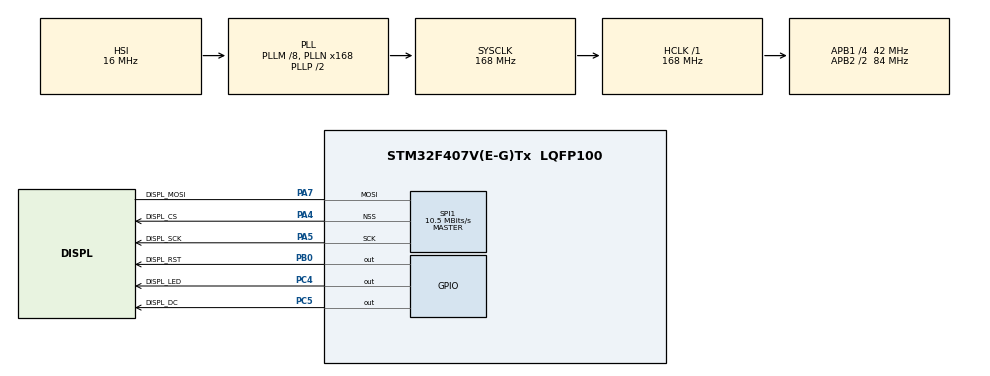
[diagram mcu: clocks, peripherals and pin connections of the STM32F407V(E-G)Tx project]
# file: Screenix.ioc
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Dma.Request0=SPI1_TX
Dma.SPI1_TX.0.Direction=DMA_MEMORY_TO_PERIPH
Dma.SPI1_TX.0.FIFOMode=DMA_FIFOMODE_DISABLE
Dma.SPI1_TX.0.Instance=DMA2_Stream3
Dma.SPI1_TX.0.MemDataAlignment=DMA_MDATAALIGN_BYTE
Dma.SPI1_TX.0.MemInc=DMA_MINC_ENABLE
Dma.SPI1_TX.0.Mode=DMA_NORMAL
Dma.SPI1_TX.0.PeriphDataAlignment=DMA_PDATAALIGN_BYTE
Dma.SPI1_TX.0.PeriphInc=DMA_PINC_DISABLE
Dma.SPI1_TX.0.Priority=DMA_PRIORITY_LOW
Mcu.Family=STM32F4
Mcu.Name=STM32F407V(E-G)Tx
Mcu.Package=LQFP100
NVIC.DMA2_Stream3_IRQn=true\:0\:0\:false\:false\:true\:false\:true\:true
NVIC.PriorityGroup=NVIC_PRIORITYGROUP_4
NVIC.SPI1_IRQn=true\:0\:0\:false\:false\:true\:true\:true\:true
PA13.Mode=Serial_Wire
PA13.Signal=SYS_JTMS-SWDIO
PA14.Mode=Serial_Wire
PA14.Signal=SYS_JTCK-SWCLK
PA4.GPIO_Label=DISPL_CS
PA4.Mode=NSS_Signal_Hard_Output
PA4.Signal=SPI1_NSS
PA5.GPIO_Label=DISPL_SCK
PA5.Mode=Simplex_Bidirectional_Master
PA5.Signal=SPI1_SCK
PA7.GPIO_Label=DISPL_MOSI
PA7.Mode=Simplex_Bidirectional_Master
PA7.Signal=SPI1_MOSI
PB0.GPIO_Label=DISPL_RST
PB0.GPIO_Speed=GPIO_SPEED_FREQ_VERY_HIGH
PB0.Signal=GPIO_Output
PC4.GPIO_Label=DISPL_LED
PC4.GPIO_Speed=GPIO_SPEED_FREQ_VERY_HIGH
PC4.Signal=GPIO_Output
PC5.GPIO_Label=DISPL_DC
PC5.GPIO_Speed=GPIO_SPEED_FREQ_VERY_HIGH
PC5.Signal=GPIO_Output
PH0-OSC_IN.Mode=HSE-External-Oscillator
PH0-OSC_IN.Signal=RCC_OSC_IN
PH1-OSC_OUT.Mode=HSE-External-Oscillator
PH1-OSC_OUT.Signal=RCC_OSC_OUT
ProjectManager.HeapSize=0x200
ProjectManager.StackSize=0x400
ProjectManager.TargetToolchain=Makefile
RCC.48MHZClocksFreq_Value=84000000
RCC.AHBFreq_Value=168000000
RCC.APB1CLKDivider=RCC_HCLK_DIV4
RCC.APB1Freq_Value=42000000
RCC.APB1TimFreq_Value=84000000
RCC.APB2CLKDivider=RCC_HCLK_DIV2
RCC.APB2Freq_Value=84000000
RCC.APB2TimFreq_Value=168000000
RCC.CortexFreq_Value=168000000
RCC.HCLKFreq_Value=168000000
RCC.HSE_VALUE=25000000
RCC.HSI_VALUE=16000000
RCC.LSE_VALUE=32768
RCC.PLLM=8
RCC.PLLN=168
RCC.SYSCLKFreq_VALUE=168000000
RCC.SYSCLKSource=RCC_SYSCLKSOURCE_PLLCLK
RCC.VCOOutputFreq_Value=336000000
SPI1.BaudRatePrescaler=SPI_BAUDRATEPRESCALER_8
SPI1.CalculateBaudRate=10.5 MBits/s
SPI1.Direction=SPI_DIRECTION_1LINE
SPI1.Mode=SPI_MODE_MASTER
SPI1.VirtualNSS=VM_NSSHARD
SPI1.VirtualType=VM_MASTER
board=custom

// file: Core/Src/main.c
/* USER CODE BEGIN Header */
/**
 ******************************************************************************
 * @file           : main.c
 * @brief          : Main program body
 ******************************************************************************
 * @attention
 *
 * Copyright (c) 2024 STMicroelectronics.
 * All rights reserved.
 *
 * This software is licensed under terms that can be found in the LICENSE file
 * in the root directory of this software component.
 * If no LICENSE file comes with this software, it is provided AS-IS.
 *
 ******************************************************************************
 */
/* USER CODE END Header */
#include "main.h"
#include "dma.h"
#include "spi.h"
#include "gpio.h"

/* USER CODE BEGIN PV */
uint8_t sos;

/* USER CODE END PV */

void SystemClock_Config(void);

int main(void)
{

  /* MCU Configuration--------------------------------------------------------*/

  /* Reset of all peripherals, Initializes the Flash interface and the Systick. */
  HAL_Init();

  /* Configure the system clock */
  SystemClock_Config();

  /* Initialize all configured peripherals */
  MX_GPIO_Init();
  MX_DMA_Init();
  MX_SPI1_Init();
  /* USER CODE BEGIN 2 */
  Displ_Init(Displ_Orientat_0); // initialize the display and set the initial display orientation (here is orientaton: 0�) - THIS FUNCTION MUST PRECEED ANY OTHER DISPLAY FUNCTION CALL.
  Displ_CLS(BLACK);             // after initialization (above) and before turning on backlight (below), you can draw the initial display appearance. (here I'm just clearing display with a black background)
                                // Displ_WChar(0, 0, 65, Font24, 1, GREEN, BLACK);
  Displ_WString(20, 52, "12:05", Font24, 1, GREEN, BLACK);
  // Displ_WString(10, 10, "Set time:", Font16, 1, YELLOW, BLACK);
  // Displ_WString(10, 10, "Set alarm:", Font16, 1, YELLOW, BLACK);
  Displ_WString(15, 30, "ALARM!", Font24, 1, RED, BLACK);

  Displ_BackLight('I'); // initialize backlight and turn it on at init level
  Displ_BackLight('F');

  /* USER CODE END 2 */

  /* Infinite loop */
  /* USER CODE BEGIN WHILE */
  while (1)
  {
    // Displ_PerfTest();
    /* USER CODE END WHILE */

  }
}

void SystemClock_Config(void)
{
  RCC_OscInitTypeDef RCC_OscInitStruct = {0};
  RCC_ClkInitTypeDef RCC_ClkInitStruct = {0};

  /** Configure the main internal regulator output voltage
   */
  __HAL_RCC_PWR_CLK_ENABLE();
  __HAL_PWR_VOLTAGESCALING_CONFIG(PWR_REGULATOR_VOLTAGE_SCALE1);

  /** Initializes the RCC Oscillators according to the specified parameters
   * in the RCC_OscInitTypeDef structure.
   */
  RCC_OscInitStruct.OscillatorType = RCC_OSCILLATORTYPE_HSI;
  RCC_OscInitStruct.HSIState = RCC_HSI_ON;
  RCC_OscInitStruct.HSICalibrationValue = RCC_HSICALIBRATION_DEFAULT;
  RCC_OscInitStruct.PLL.PLLState = RCC_PLL_ON;
  RCC_OscInitStruct.PLL.PLLSource = RCC_PLLSOURCE_HSI;
  RCC_OscInitStruct.PLL.PLLM = 8;
  RCC_OscInitStruct.PLL.PLLN = 168;
  RCC_OscInitStruct.PLL.PLLP = RCC_PLLP_DIV2;
  RCC_OscInitStruct.PLL.PLLQ = 4;
  if (HAL_RCC_OscConfig(&RCC_OscInitStruct) != HAL_OK)
  {
    Error_Handler();
  }

  /** Initializes the CPU, AHB and APB buses clocks
   */
  RCC_ClkInitStruct.ClockType = RCC_CLOCKTYPE_HCLK | RCC_CLOCKTYPE_SYSCLK | RCC_CLOCKTYPE_PCLK1 | RCC_CLOCKTYPE_PCLK2;
  RCC_ClkInitStruct.SYSCLKSource = RCC_SYSCLKSOURCE_PLLCLK;
  RCC_ClkInitStruct.AHBCLKDivider = RCC_SYSCLK_DIV1;
  RCC_ClkInitStruct.APB1CLKDivider = RCC_HCLK_DIV4;
  RCC_ClkInitStruct.APB2CLKDivider = RCC_HCLK_DIV2;

  if (HAL_RCC_ClockConfig(&RCC_ClkInitStruct, FLASH_LATENCY_5) != HAL_OK)
  {
    Error_Handler();
  }
}

void Error_Handler(void)
{
  __disable_irq();
  while (1)
  {
  }
}
